AUTOSAR XML (schema 00048)
package /HuaweiMDC/PlatformApplication/BodyCenterApplication/BodyProcessStartupConfig
  startup config set BodyStartupConfigSet
    startup config BodyStartupConfig: scheduling-policy=SCHEDULING-POLICY-ROUND-ROBIN, scheduling-priority=12
package /HuaweiMDC/PlatformApplication/BodyCenterApplication/Execution
  executable libbody_a_cm
    root sw component prototype libbody_a_cm: application-type=libbody_a_cm
package /HuaweiMDC/PlatformApplication/BodyCenterApplication/SwComponent
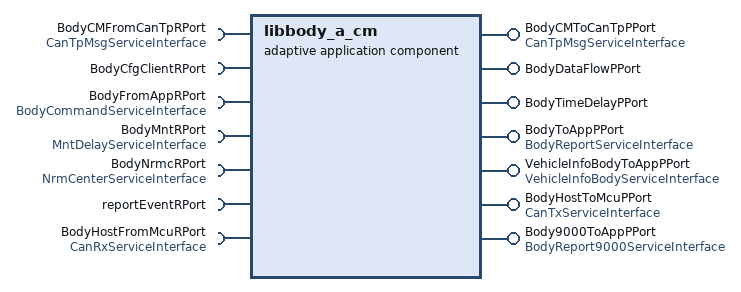
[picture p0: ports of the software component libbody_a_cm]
  adaptive application sw component type libbody_a_cm
    require port BodyCMFromCanTpRPort: required-interface=CanTpMsgServiceInterface
    provide port BodyCMToCanTpPPort: provided-interface=CanTpMsgServiceInterface
    require port BodyCfgClientRPort
    provide port BodyDataFlowPPort
    require port BodyFromAppRPort: required-interface=BodyCommandServiceInterface
    require port BodyMntRPort: required-interface=MntDelayServiceInterface
    require port BodyNrmcRPort: required-interface=NrmCenterServiceInterface
    provide port BodyTimeDelayPPort
    provide port BodyToAppPPort: provided-interface=BodyReportServiceInterface
    require port reportEventRPort
    provide port VehicleInfoBodyToAppPPort: provided-interface=VehicleInfoBodyServiceInterface
    provide port BodyHostToMcuPPort: provided-interface=CanTxServiceInterface
    require port BodyHostFromMcuRPort: required-interface=CanRxServiceInterface
    provide port Body9000ToAppPPort: provided-interface=BodyReport9000ServiceInterface
